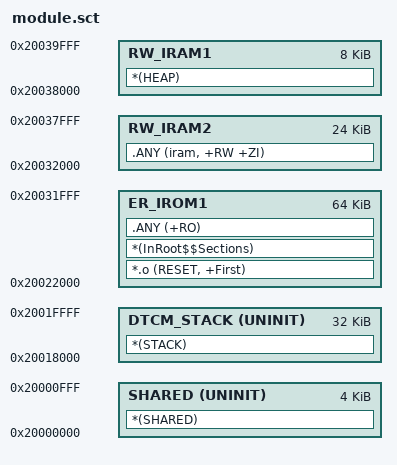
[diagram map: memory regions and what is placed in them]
; *************************************************************
; *** Scatter-Loading Description File generated by uVision ***
; *************************************************************

LR_IROM1 0x20022000 0x00010000  {    ; load region size_region
  ER_IROM1 0x20022000 0x00010000  {  ; load address = execution address
   *.o (RESET, +First)
   *(InRoot$$Sections)
   .ANY (+RO)
  }
  RW_IRAM2 0x20032000 0x00006000  {  ; RW data
   .ANY (iram, +RW +ZI)
  }
  SHARED 0x20000000 UNINIT 0x00001000  {  ; DTCM
    *(SHARED)
  }
  DTCM_STACK 0x20018000 UNINIT 0x00008000  {  ; DTCM    
   *(STACK)
  }
  RW_IRAM1 0x20038000 0x00002000  {  ; RW data
   *(HEAP)
  }
}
